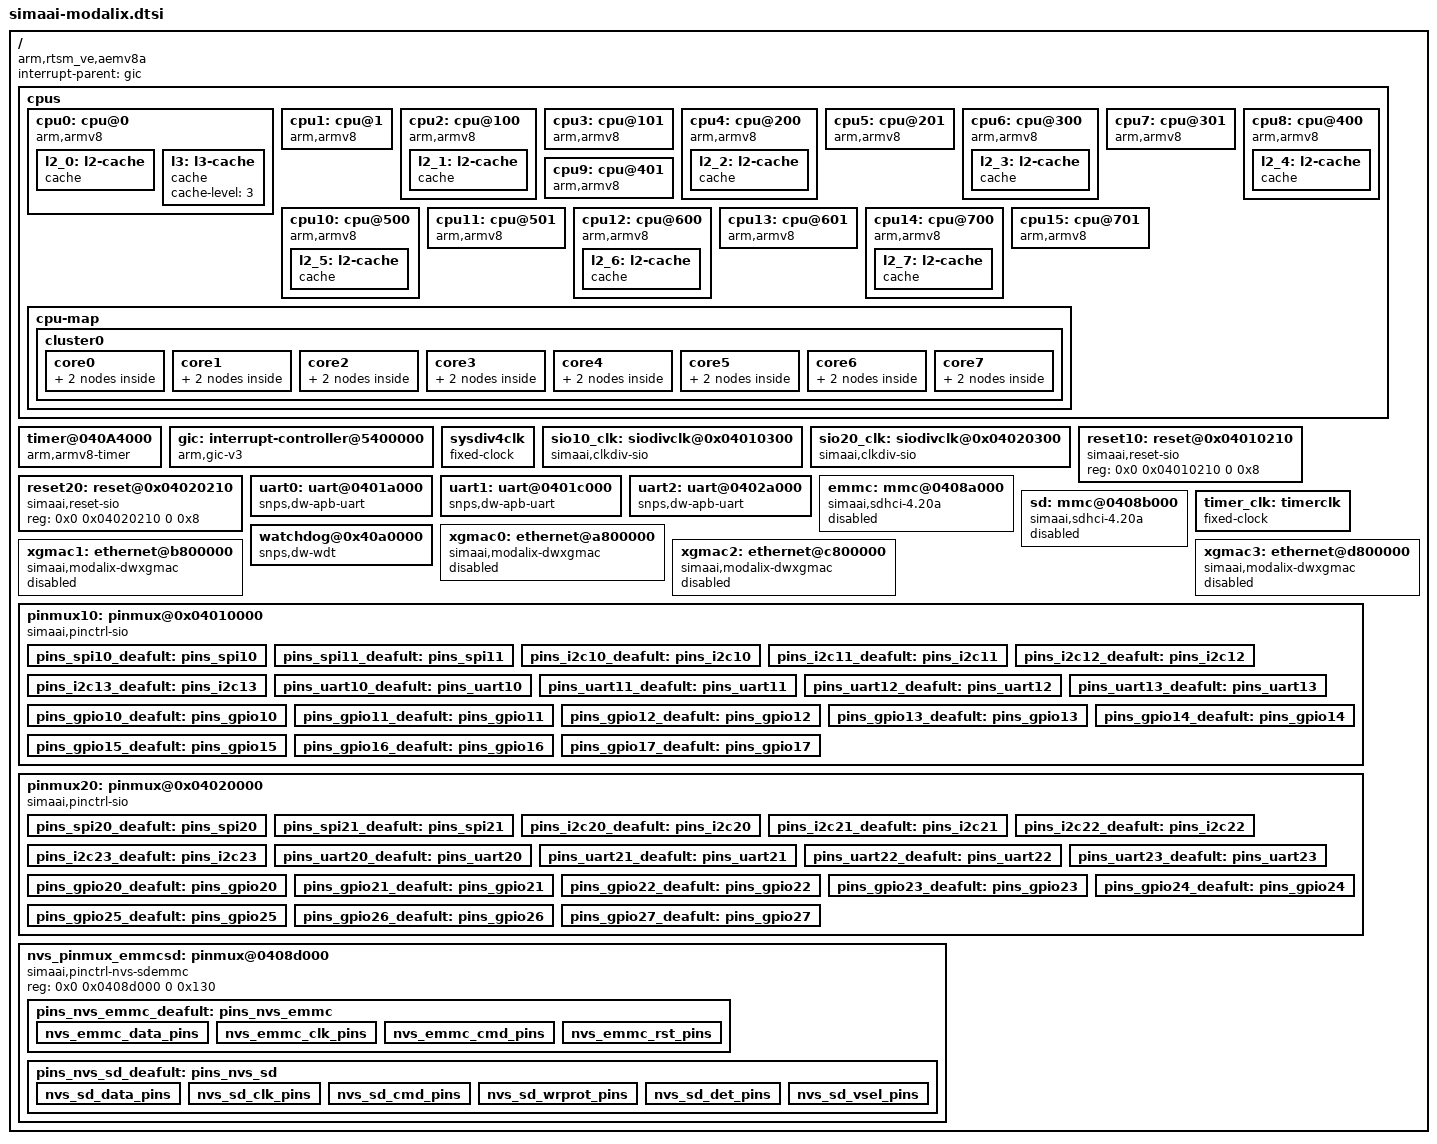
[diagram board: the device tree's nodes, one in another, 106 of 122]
// SPDX-License-Identifier: (GPL-2.0+ OR MIT)
/*
 * Copyright (c) 2023 SiMa ai
 */

/dts-v1/;

#include <dt-bindings/interrupt-controller/irq.h>
#include <dt-bindings/interrupt-controller/arm-gic.h>
#include <dt-bindings/pinctrl/pinctrl-simaai-sio.h>

/ {
        compatible = "arm,rtsm_ve,aemv8a","arm,vexpress";
        interrupt-parent = <&gic>;
		    #address-cells = <2>;
		    #size-cells = <2>;

        cpus {
               #address-cells = <2>;
               #size-cells = <0>;
               
                cpu0: cpu@0 {
                        device_type = "cpu";
                        compatible = "arm,armv8";
                        reg = <0x0 0x0>;
                        enable-method = "spin-table";
                        cpu-release-addr = <0x10 0x0000fff0>;
                        next-level-cache = <&l2_0>;
                        l2_0: l2-cache {
                                compatible = "cache";
                                cache-level = <2>;
                                next-level-cache = <&l3>;
                        };
                        l3: l3-cache {
                                compatible = "cache";
                                cache-level = <3>;
                        };
                };

                cpu1: cpu@1 {
                        device_type = "cpu";
                        compatible = "arm,armv8";
                        reg = <0x0 0x1>;
                        enable-method = "spin-table";
                        cpu-release-addr = <0x10 0x0000fff0>;
                        next-level-cache = <&l2_0>;
                };

                cpu2: cpu@100 {
                        device_type = "cpu";
                        compatible = "arm,armv8";
                        reg = <0x0 0x100>;
                        enable-method = "spin-table";
                        cpu-release-addr = <0x10 0x0000fff0>;
                        next-level-cache = <&l2_1>;
                        l2_1: l2-cache {
                                compatible = "cache";
                                cache-level = <2>;
                                next-level-cache = <&l3>;
                        };
                };

                cpu3: cpu@101 {
                        device_type = "cpu";
                        compatible = "arm,armv8";
                        reg = <0x0 0x101>;
                        enable-method = "spin-table";
                        cpu-release-addr = <0x10 0x0000fff0>;
                        next-level-cache = <&l2_1>;
                };

                cpu4: cpu@200 {
                        device_type = "cpu";
                        compatible = "arm,armv8";
                        reg = <0x0 0x10000>;
                        enable-method = "spin-table";
                        cpu-release-addr = <0x10 0x0000fff0>;
                        next-level-cache = <&l2_2>;
                        l2_2: l2-cache {
                                compatible = "cache";
                                cache-level = <2>;
                                next-level-cache = <&l3>;
                        };
                };

                cpu5: cpu@201 {
                        device_type = "cpu";
                        compatible = "arm,armv8";
                        reg = <0x0 0x10001>;
                        enable-method = "spin-table";
                        cpu-release-addr = <0x10 0x0000fff0>;
                        next-level-cache = <&l2_2>;
                };

                cpu6: cpu@300 {
                        device_type = "cpu";
                        compatible = "arm,armv8";
                        reg = <0x0 0x10100>;
                        enable-method = "spin-table";
                        cpu-release-addr = <0x10 0x0000fff0>;
                        next-level-cache = <&l2_3>;
                        l2_3: l2-cache {
                                compatible = "cache";
                                cache-level = <2>;
                                next-level-cache = <&l3>;
                        };
                };

                cpu7: cpu@301 {
                        device_type = "cpu";
                        compatible = "arm,armv8";
                        reg = <0x0 0x10101>;
                        enable-method = "spin-table";
                        cpu-release-addr = <0x10 0x0000fff0>;
                        next-level-cache = <&l2_3>;
                };

                cpu8: cpu@400 {
                        device_type = "cpu";
                        compatible = "arm,armv8";
                        reg = <0x1 0x0>;
                        enable-method = "spin-table";
                        cpu-release-addr = <0x10 0x0000fff0>;
                        next-level-cache = <&l2_4>;
                        l2_4: l2-cache {
                                compatible = "cache";
                                cache-level = <2>;
                                next-level-cache = <&l3>;
                        };
                };

                cpu9: cpu@401 {
                        device_type = "cpu";
                        compatible = "arm,armv8";
                        reg = <0x1 0x1>;
                        enable-method = "spin-table";
                        cpu-release-addr = <0x10 0x0000fff0>;
                        next-level-cache = <&l2_4>;
                };

                cpu10: cpu@500 {
                        device_type = "cpu";
                        compatible = "arm,armv8";
                        reg = <0x1 0x100>;
                        enable-method = "spin-table";
                        cpu-release-addr = <0x10 0x0000fff0>;
                        next-level-cache = <&l2_5>;
                        l2_5: l2-cache {
                                compatible = "cache";
                                cache-level = <2>;
                                next-level-cache = <&l3>;
                        };
                };

                cpu11: cpu@501 {
                        device_type = "cpu";
                        compatible = "arm,armv8";
                        reg = <0x1 0x101>;
                        enable-method = "spin-table";
                        cpu-release-addr = <0x10 0x0000fff0>;
                        next-level-cache = <&l2_5>;
                };

                cpu12: cpu@600 {
                        device_type = "cpu";
                        compatible = "arm,armv8";
                        reg = <0x1 0x10000>;
                        enable-method = "spin-table";
                        cpu-release-addr = <0x10 0x0000fff0>;
                        next-level-cache = <&l2_6>;
                        l2_6: l2-cache {
                                compatible = "cache";
                                cache-level = <2>;
                                next-level-cache = <&l3>;
                        };
                };

                cpu13: cpu@601 {
                        device_type = "cpu";
                        compatible = "arm,armv8";
                        reg = <0x1 0x10001>;
                        enable-method = "spin-table";
                        cpu-release-addr = <0x10 0x0000fff0>;
                        next-level-cache = <&l2_6>;
                };

                cpu14: cpu@700 {
                        device_type = "cpu";
                        compatible = "arm,armv8";
                        reg = <0x1 0x10100>;
                        enable-method = "spin-table";
                        cpu-release-addr = <0x10 0x0000fff0>;
                        next-level-cache = <&l2_7>;
                        l2_7: l2-cache {
                                compatible = "cache";
                                cache-level = <2>;
                                next-level-cache = <&l3>;
                        };
                };

                cpu15: cpu@701 {
                        device_type = "cpu";
                        compatible = "arm,armv8";
                        reg = <0x1 0x10101>;
                        enable-method = "spin-table";
                        cpu-release-addr = <0x10 0x0000fff0>;
                        next-level-cache = <&l2_7>;
                };

                cpu-map {
                  cluster0 {
                    core0 {
                      thread0 {
                        cpu = <&cpu0>;
                      };
                      thread1 {
                        cpu = <&cpu1>;
                      };
                    };

                    core1 {
                      thread0 {
                        cpu = <&cpu2>;
                      };
                      thread1 {
                        cpu = <&cpu3>;
                      };
                    };

                    core2 {
                      thread0 {
                        cpu = <&cpu4>;
                      };
                      thread1 {
                        cpu = <&cpu5>;
                      };
                    };

                    core3 {
                      thread0 {
                        cpu = <&cpu6>;
                      };
                      thread1 {
                        cpu = <&cpu7>;
                      };
                    };

                    core4 {
                      thread0 {
                        cpu = <&cpu8>;
                      };
                      thread1 {
                        cpu = <&cpu9>;
                      };
                    };

                    core5 {
                      thread0 {
                        cpu = <&cpu10>;
                      };
                      thread1 {
                        cpu = <&cpu11>;
                      };
                    };

                    core6 {
                      thread0 {
                        cpu = <&cpu12>;
                      };
                      thread1 {
                        cpu = <&cpu13>;
                      };
                    };

                    core7 {
                      thread0 {
                        cpu = <&cpu14>;
                      };
                      thread1 {
                        cpu = <&cpu15>;
                      };
                    };
                  };
                };
            };

        timer@040A4000 {
                compatible = "arm,armv8-timer";
                interrupts = <0x1 0x10 0xff08 0x1 0xf 0xff08 0x1 0xe 0xff08 0x1 0xd 0xff08>;
                clock-frequency = <25000000>;
        };

        gic: interrupt-controller@5400000 {
                compatible = "arm,gic-v3";
                #interrupt-cells = <3>;
                #address-cells = <2>;
                #size-cells = <2>;
                ranges;
                interrupt-controller;
                reg = <0x0 0x5400000 0x0 0x10000>, 
                      <0x0 0x5440000 0x0 0x200000>;
        };

        sysdiv4clk: sysdiv4clk {
                compatible = "fixed-clock";
                #clock-cells = <0>;
                clock-frequency = <250000000>;
                clock-output-names = "sysdiv4clk";
        };

	sio10_clk: siodivclk@0x04010300 {
		compatible = "simaai,clkdiv-sio";
		reg = <0x0 0x04010300 0 0x28>;
		#clock-cells = <1>;
		clocks = <&sysdiv4clk>;
		simaai,ignore-unused = <0x200>;
	};

	sio20_clk: siodivclk@0x04020300 {
		compatible = "simaai,clkdiv-sio";
		reg = <0x0 0x04020300 0 0x28>;
		#clock-cells = <1>;
		clocks = <&sysdiv4clk>;
	};

	reset10: reset@0x04010210 {
		compatible = "simaai,reset-sio";
		reg = <0x0 0x04010210 0 0x8>;
		#reset-cells = <1>;
	};

	reset20: reset@0x04020210 {
		compatible = "simaai,reset-sio";
		reg = <0x0 0x04020210 0 0x8>;
		#reset-cells = <1>;
	};

        uart0: uart@0401a000 {
                compatible = "snps,dw-apb-uart";
                reg = <0x0 0x0401a000 0x0 0x100>;
                interrupts = <GIC_SPI 0x13f IRQ_TYPE_LEVEL_HIGH>;
                reg-io-width = <4>;
                reg-shift = <2>;
                clocks = <&sio10_clk SIMAAI_SIO_DEV_UART2>;
                resets = <&reset10 SIMAAI_SIO_DEV_UART2>;
                pinctrl-0 = <&pins_uart12_deafult>;
                pinctrl-names = "default";
        };

        uart1: uart@0401c000 {
                compatible = "snps,dw-apb-uart";
                reg = <0x0 0x0401c000 0x0 0x100>;
                interrupts = <GIC_SPI 0x143 IRQ_TYPE_LEVEL_HIGH>;
                reg-io-width = <4>;
                reg-shift = <2>;
                clocks = <&sio10_clk SIMAAI_SIO_DEV_UART3>;
                resets = <&reset10 SIMAAI_SIO_DEV_UART3>;
                pinctrl-0 = <&pins_uart13_deafult>;
                pinctrl-names = "default";
        };

        uart2: uart@0402a000 {
                compatible = "snps,dw-apb-uart";
                reg = <0x0 0x0402a000 0x0 0x100>;
                interrupts = <GIC_SPI 0x159 IRQ_TYPE_LEVEL_HIGH>;
                reg-io-width = <4>;
                reg-shift = <2>;
                clocks = <&sio20_clk SIMAAI_SIO_DEV_UART2>;
                resets = <&reset20 SIMAAI_SIO_DEV_UART2>;
                pinctrl-0 = <&pins_uart22_deafult>;
                pinctrl-names = "default";
        };

        emmc: mmc@0408a000 {
		compatible = "simaai,sdhci-4.20a";
		reg = <0x0 0x0408a000 0 0x1000>;
		bus-width = <8>;
		max-frequency= <400000000>;
		pinctrl-0 = <&pins_nvs_emmc_deafult>;
		pinctrl-names = "default";
		status = "disabled";
	};

	sd: mmc@0408b000 {
		compatible = "simaai,sdhci-4.20a";
		reg = <0x0 0x0408b000 0 0x1000>;
		bus-width = <4>;
		max-frequency= <400000000>;
		pinctrl-0 = <&pins_nvs_sd_deafult>;
		pinctrl-names = "default";
		no-1-8-v;
		status = "disabled";
	};

	timer_clk: timerclk {
		compatible = "fixed-clock";
		#clock-cells = <0>;
		clock-frequency = <25000000>;
		clock-output-names = "timerclk";
	};

	watchdog@0x40a0000 {
		compatible = "snps,dw-wdt";
		reg = <0x0 0x40a0000 0x0 0x1000>;
		clocks = <&timer_clk>;
		clock-names = "core";
		status = "okay";
	};

	xgmac0: ethernet@a800000 {
		compatible = "simaai,modalix-dwxgmac", "snps,dwxgmac-2.10", "snps,dwxgmac";
		reg = <0x0 0xa800000 0x0 0x3180>,
		      <0x0 0xa040000 0x0 0x7c0000>;
		reg-names = "gmac", "xpcs";
		snps,multicast-filter-bins = <256>;
		snps,perfect-filter-entries = <128>;
		rx-fifo-depth = <16384>;
		tx-fifo-depth = <16384>;
		snps,pbl = <32>;
		clocks = <&sysdiv4clk>;
		clock-names = "stmmaceth";
		phy-mode = "xgmii";
		status = "disabled";
	};

	xgmac1: ethernet@b800000 {
		compatible = "simaai,modalix-dwxgmac", "snps,dwxgmac-2.10", "snps,dwxgmac";
		reg = <0x0 0xb800000 0x0 0x3180>,
		      <0x0 0xb040000 0x0 0x7c0000>;
		reg-names = "gmac", "xpcs";
		snps,multicast-filter-bins = <256>;
		snps,perfect-filter-entries = <128>;
		rx-fifo-depth = <16384>;
		tx-fifo-depth = <16384>;
		snps,pbl = <32>;
		clocks = <&sysdiv4clk>;
		clock-names = "stmmaceth";
		phy-mode = "xgmii";
		status = "disabled";
	};

	xgmac2: ethernet@c800000 {
		compatible = "simaai,modalix-dwxgmac", "snps,dwxgmac-2.10", "snps,dwxgmac";
		reg = <0x0 0xc800000 0x0 0x3180>,
		      <0x0 0xc040000 0x0 0x7c0000>;
		reg-names = "gmac", "xpcs";
		snps,multicast-filter-bins = <256>;
		snps,perfect-filter-entries = <128>;
		rx-fifo-depth = <16384>;
		tx-fifo-depth = <16384>;
		snps,pbl = <32>;
		clocks = <&sysdiv4clk>;
		clock-names = "stmmaceth";
		phy-mode = "xgmii";
		status = "disabled";
	};

	xgmac3: ethernet@d800000 {
		compatible = "simaai,modalix-dwxgmac", "snps,dwxgmac-2.10", "snps,dwxgmac";
		reg = <0x0 0xd800000 0x0 0x3180>,
		      <0x0 0xd040000 0x0 0x7c0000>;
		reg-names = "gmac", "xpcs";
		snps,multicast-filter-bins = <256>;
		snps,perfect-filter-entries = <128>;
		rx-fifo-depth = <16384>;
		tx-fifo-depth = <16384>;
		snps,pbl = <32>;
		clocks = <&sysdiv4clk>;
		clock-names = "stmmaceth";
		phy-mode = "xgmii";
		status = "disabled";
	};

	pinmux10: pinmux@0x04010000 {
		compatible = "simaai,pinctrl-sio";
		reg = <0x0 0x04010000 0 0x208>, <0x0 0x04011008 0 0x4>;
		reg-names = "ctl", "gpio";

		pins_spi10_deafult: pins_spi10 {
			function = "spi";
			groups = "spi0_group";
		};

		pins_spi11_deafult: pins_spi11 {
			function = "spi";
			groups = "spi1_group";
		};

		pins_i2c10_deafult: pins_i2c10 {
			function = "i2c";
			groups = "i2c0_group";
		};

		pins_i2c11_deafult: pins_i2c11 {
			function = "i2c";
			groups = "i2c1_group";
		};

		pins_i2c12_deafult: pins_i2c12 {
			function = "i2c";
			groups = "i2c2_group";
		};

		pins_i2c13_deafult: pins_i2c13 {
			function = "i2c";
			groups = "i2c3_group";
		};

		pins_uart10_deafult: pins_uart10 {
			function = "uart";
			groups = "uart0_group";
		};

		pins_uart11_deafult: pins_uart11 {
			function = "uart";
			groups = "uart1_group";
		};

		pins_uart12_deafult: pins_uart12 {
			function = "uart";
			groups = "uart2_group";
		};

		pins_uart13_deafult: pins_uart13 {
			function = "uart";
			groups = "uart3_group";
		};

		pins_gpio10_deafult: pins_gpio10 {
			function = "gpio";
			groups = "gpio0_group";
		};

		pins_gpio11_deafult: pins_gpio11 {
			function = "gpio";
			groups = "gpio1_group";
		};

		pins_gpio12_deafult: pins_gpio12 {
			function = "gpio";
			groups = "gpio2_group";
		};

		pins_gpio13_deafult: pins_gpio13 {
			function = "gpio";
			groups = "gpio3_group";
		};

		pins_gpio14_deafult: pins_gpio14 {
			function = "gpio";
			groups = "gpio4_group";
		};

		pins_gpio15_deafult: pins_gpio15 {
			function = "gpio";
			groups = "gpio5_group";
		};

		pins_gpio16_deafult: pins_gpio16 {
			function = "gpio";
			groups = "gpio6_group";
		};

		pins_gpio17_deafult: pins_gpio17 {
			function = "gpio";
			groups = "gpio7_group";
		};
	};

	pinmux20: pinmux@0x04020000 {
		compatible = "simaai,pinctrl-sio";
		reg = <0x0 0x04020000 0 0x208>, <0x0 0x04021008 0 0x4>;
		reg-names = "ctl", "gpio";

		pins_spi20_deafult: pins_spi20 {
			function = "spi";
			groups = "spi0_group";
		};

		pins_spi21_deafult: pins_spi21 {
			function = "spi";
			groups = "spi1_group";
		};

		pins_i2c20_deafult: pins_i2c20 {
			function = "i2c";
			groups = "i2c0_group";
		};

		pins_i2c21_deafult: pins_i2c21 {
			function = "i2c";
			groups = "i2c1_group";
		};

		pins_i2c22_deafult: pins_i2c22 {
			function = "i2c";
			groups = "i2c2_group";
		};

		pins_i2c23_deafult: pins_i2c23 {
			function = "i2c";
			groups = "i2c3_group";
		};

		pins_uart20_deafult: pins_uart20 {
			function = "uart";
			groups = "uart0_group";
		};

		pins_uart21_deafult: pins_uart21 {
			function = "uart";
			groups = "uart1_group";
		};

		pins_uart22_deafult: pins_uart22 {
			function = "uart";
			groups = "uart2_group";
		};

		pins_uart23_deafult: pins_uart23 {
			function = "uart";
			groups = "uart3_group";
		};

		pins_gpio20_deafult: pins_gpio20 {
			function = "gpio";
			groups = "gpio0_group";
		};

		pins_gpio21_deafult: pins_gpio21 {
			function = "gpio";
			groups = "gpio1_group";
		};

		pins_gpio22_deafult: pins_gpio22 {
			function = "gpio";
			groups = "gpio2_group";
		};

		pins_gpio23_deafult: pins_gpio23 {
			function = "gpio";
			groups = "gpio3_group";
		};

		pins_gpio24_deafult: pins_gpio24 {
			function = "gpio";
			groups = "gpio4_group";
		};

		pins_gpio25_deafult: pins_gpio25 {
			function = "gpio";
			groups = "gpio5_group";
		};

		pins_gpio26_deafult: pins_gpio26 {
			function = "gpio";
			groups = "gpio6_group";
		};

		pins_gpio27_deafult: pins_gpio27 {
			function = "gpio";
			groups = "gpio7_group";
		};
	};

	nvs_pinmux_emmcsd: pinmux@0408d000 {
		compatible = "simaai,pinctrl-nvs-sdemmc";
		reg = <0x0 0x0408d000 0 0x130>;

		pins_nvs_emmc_deafult: pins_nvs_emmc {
			nvs_emmc_data_pins {
				pins = "EMMC_D0", "EMMC_D1", "EMMC_D2", "EMMC_D3",
					"EMMC_D4", "EMMC_D5", "EMMC_D6", "EMMC_D7";
				input-enable;
				output-enable;
				drive-strength = <7>;
			};
			nvs_emmc_clk_pins {
				pins = "EMMC_CLK";
				input-enable;
				output-enable;
				bias-pull-up;
				drive-strength = <7>;
			};
			nvs_emmc_cmd_pins {
				pins = "EMMC_CMD";
				input-enable;
				output-enable;
				drive-strength = <7>;
			};
			nvs_emmc_rst_pins {
				pins = "EMMC_RST";
				input-enable;
				output-enable;
				bias-pull-up;
				drive-strength = <7>;
			};
		};

		pins_nvs_sd_deafult: pins_nvs_sd {
			nvs_sd_data_pins {
				pins = "SDIO_D0", "SDIO_D1", "SDIO_D2", "SDIO_D3";
				input-enable;
				output-enable;
				drive-strength = <7>;
			};
			nvs_sd_clk_pins {
				pins = "SDIO_CLK";
				input-enable;
				output-enable;
				bias-pull-up;
				drive-strength = <7>;
			};
			nvs_sd_cmd_pins {
				pins = "SDIO_CMD";
				input-enable;
				output-enable;
				drive-strength = <7>;
			};
			nvs_sd_wrprot_pins {
				pins = "SDIO_WP";
				input-enable;
				output-enable;
				bias-pull-up;
				drive-strength = <7>;
			};
			nvs_sd_det_pins {
				pins = "SDIO_DET";
				input-enable;
				output-enable;
				bias-pull-up;
				drive-strength = <7>;
			};
			nvs_sd_vsel_pins {
				pins = "SDIO_VSEL";
				output-enable;
				drive-strength = <7>;
			};
		};
	};
};
